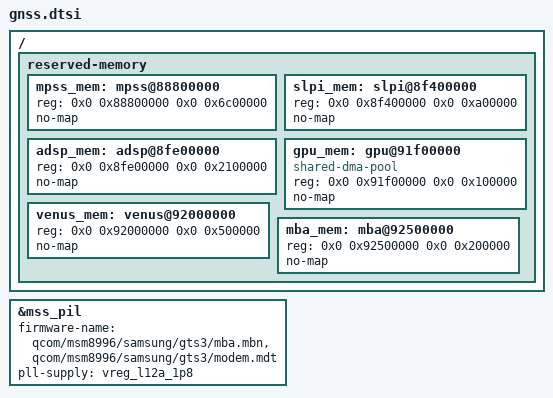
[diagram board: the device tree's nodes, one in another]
// SPDX-License-Identifier: BSD-3-Clause
/*
 * GNSS test fragment for both models, included by test-gnss.dts (SM-T820)
 * and test-gnss-lte.dts (SM-T825). See docs/gnss.md.
 *
 * The GNSS engine runs on the modem DSP (MSS, Hexagon QDSP6 v5.5), on
 * both models. The SM-T820 (APQ8096) carries a GNSS-only modem image
 * (Product_Flavor "modemlite" in the modem partition's verinfo), the
 * SM-T825 the full LTE one. Linux boots the MSS with qcom_q6v5_mss, rmtfs
 * serves it the modemst1/modemst2/fsg/fsc partitions, and the location
 * service (QMI LOC) is reached over QRTR. The MSS has auto_boot off:
 * "rmtfs -s" starts it once the file service is up.
 *
 * Memory. The SM-T820 modem image spans 0x88800000-0x8f400000 (0x6c00000
 * bytes from its lowest segment to the end of its last one): that is the
 * stock modem_mem carve-out (downstream msm8996-sec-common.dtsi) and
 * where the stock kernel loads it. msm8996.dtsi's mpss_mem is 0x6200000
 * and qcom_q6v5_mss refuses a segment that ends past it, so mpss_mem
 * grows to the stock size. That covers msm8996.dtsi's adsp_mem, so the
 * regions after the modem move to where the stock 3.18 kernel puts them
 * on the SM-T820 (dmesg of 2026-10-06, all relocatable images): SLPI at
 * 0x8f400000, ADSP at 0x8fe00000, the A530 zap shader at 0x91f00000.
 * Venus takes the rest of the stock peripheral_region (0x8f400000 to
 * 0x92500000, which ends the reserved tail the board DT adds at
 * 0x92100000), and the MBA, which stock allocates dynamically, goes right
 * after it.
 */

/delete-node/ &mpss_mem;
/delete-node/ &slpi_mem;
/delete-node/ &adsp_mem;
/delete-node/ &gpu_mem;
/delete-node/ &venus_mem;
/delete-node/ &mba_mem;

/ {
	reserved-memory {
		/* Tail of the stock peripheral_region, now holds venus_mem */
		/delete-node/ memory@92100000;

		mpss_mem: mpss@88800000 {
			reg = <0x0 0x88800000 0x0 0x6c00000>;
			no-map;
		};

		slpi_mem: slpi@8f400000 {
			reg = <0x0 0x8f400000 0x0 0xa00000>;
			no-map;
		};

		adsp_mem: adsp@8fe00000 {
			reg = <0x0 0x8fe00000 0x0 0x2100000>;
			no-map;
		};

		gpu_mem: gpu@91f00000 {
			compatible = "shared-dma-pool";
			reg = <0x0 0x91f00000 0x0 0x100000>;
			no-map;
		};

		venus_mem: venus@92000000 {
			reg = <0x0 0x92000000 0x0 0x500000>;
			no-map;
		};

		mba_mem: mba@92500000 {
			reg = <0x0 0x92500000 0x0 0x200000>;
			no-map;
		};
	};
};

/*
 * Firmware from the tablet's own modem partition (image/mba.mbn and
 * image/modem.*), copied by gts3-firmware. PLL supply: PM8994 L12 at
 * 1.8 V, as downstream vdd_pll-supply (msm8996.dtsi qcom,mss@2080000).
 */
&mss_pil {
	firmware-name = "qcom/msm8996/samsung/gts3/mba.mbn",
			"qcom/msm8996/samsung/gts3/modem.mdt";
	pll-supply = <&vreg_l12a_1p8>;
	status = "okay";
};
